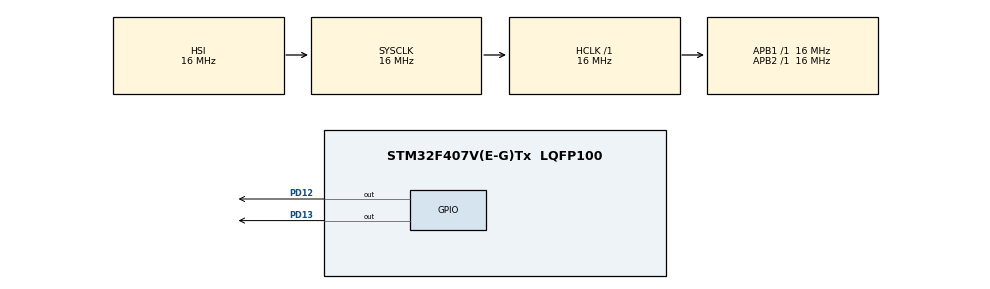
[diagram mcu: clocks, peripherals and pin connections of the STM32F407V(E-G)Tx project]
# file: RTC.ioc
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Mcu.Family=STM32F4
Mcu.Name=STM32F407V(E-G)Tx
Mcu.Package=LQFP100
NVIC.PriorityGroup=NVIC_PRIORITYGROUP_4
NVIC.RTC_Alarm_IRQn=true\:0\:0\:false\:false\:true\:true\:true\:true
PD12.Signal=GPIO_Output
PD13.Signal=GPIO_Output
ProjectManager.HeapSize=0x200
ProjectManager.StackSize=0x400
ProjectManager.TargetToolchain=STM32CubeIDE
RCC.AHBFreq_Value=16000000
RCC.APB1Freq_Value=16000000
RCC.APB2Freq_Value=16000000
RCC.CortexFreq_Value=16000000
RCC.HSE_VALUE=25000000
RCC.HSI_VALUE=16000000
RCC.LSE_VALUE=32768
RCC.SYSCLKFreq_VALUE=16000000
RCC.VCOOutputFreq_Value=192000000
RTC.Alarm=RTC_ALARM_A
RTC.AlarmDateWeekDay=4
RTC.Date=3
RTC.HourFormat=RTC_HOURFORMAT_24
RTC.Hours=23
RTC.Minutes=59
RTC.Month=RTC_MONTH_OCTOBER
RTC.Seconds=59
RTC.Seconds_A=9
RTC.WeekDay=RTC_WEEKDAY_SATURDAY
RTC.Year=0
VP_RTC_VS_RTC_Activate.Mode=RTC_Enabled
VP_RTC_VS_RTC_Alarm_A_Intern.Mode=Alarm A
VP_RTC_VS_RTC_Calendar.Mode=RTC_Calendar
board=custom

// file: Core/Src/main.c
/* USER CODE BEGIN Header */
/**
  ******************************************************************************
  * @file           : main.c
  * @brief          : Main program body
  ******************************************************************************
  * @attention
  *
  * Copyright (c) 2026 STMicroelectronics.
  * All rights reserved.
  *
  * This software is licensed under terms that can be found in the LICENSE file
  * in the root directory of this software component.
  * If no LICENSE file comes with this software, it is provided AS-IS.
  *
  ******************************************************************************
  */
/* USER CODE END Header */
#include "main.h"

RTC_HandleTypeDef hrtc;

void SystemClock_Config(void);
static void MX_GPIO_Init(void);
static void MX_RTC_Init(void);

int main(void)
{

  /* MCU Configuration--------------------------------------------------------*/

  /* Reset of all peripherals, Initializes the Flash interface and the Systick. */
  HAL_Init();

  /* Configure the system clock */
  SystemClock_Config();

  /* Initialize all configured peripherals */
  MX_GPIO_Init();
  MX_RTC_Init();

  /* Infinite loop */
  while (1)
  {

    /* USER CODE BEGIN 3 */
	  HAL_Delay(1000);
	  HAL_GPIO_TogglePin(GPIOD, GPIO_PIN_13);
  }
  /* USER CODE END 3 */
}

void SystemClock_Config(void)
{
  RCC_OscInitTypeDef RCC_OscInitStruct = {0};
  RCC_ClkInitTypeDef RCC_ClkInitStruct = {0};

  /** Configure the main internal regulator output voltage
  */
  __HAL_RCC_PWR_CLK_ENABLE();
  __HAL_PWR_VOLTAGESCALING_CONFIG(PWR_REGULATOR_VOLTAGE_SCALE1);

  /** Initializes the RCC Oscillators according to the specified parameters
  * in the RCC_OscInitTypeDef structure.
  */
  RCC_OscInitStruct.OscillatorType = RCC_OSCILLATORTYPE_HSI|RCC_OSCILLATORTYPE_LSI;
  RCC_OscInitStruct.HSIState = RCC_HSI_ON;
  RCC_OscInitStruct.HSICalibrationValue = RCC_HSICALIBRATION_DEFAULT;
  RCC_OscInitStruct.LSIState = RCC_LSI_ON;
  RCC_OscInitStruct.PLL.PLLState = RCC_PLL_NONE;
  if (HAL_RCC_OscConfig(&RCC_OscInitStruct) != HAL_OK)
  {
    Error_Handler();
  }

  /** Initializes the CPU, AHB and APB buses clocks
  */
  RCC_ClkInitStruct.ClockType = RCC_CLOCKTYPE_HCLK|RCC_CLOCKTYPE_SYSCLK
                              |RCC_CLOCKTYPE_PCLK1|RCC_CLOCKTYPE_PCLK2;
  RCC_ClkInitStruct.SYSCLKSource = RCC_SYSCLKSOURCE_HSI;
  RCC_ClkInitStruct.AHBCLKDivider = RCC_SYSCLK_DIV1;
  RCC_ClkInitStruct.APB1CLKDivider = RCC_HCLK_DIV1;
  RCC_ClkInitStruct.APB2CLKDivider = RCC_HCLK_DIV1;

  if (HAL_RCC_ClockConfig(&RCC_ClkInitStruct, FLASH_LATENCY_0) != HAL_OK)
  {
    Error_Handler();
  }
}

static void MX_RTC_Init(void)
{

  RTC_TimeTypeDef sTime = {0};
  RTC_DateTypeDef sDate = {0};
  RTC_AlarmTypeDef sAlarm = {0};

  /** Initialize RTC Only
  */
  hrtc.Instance = RTC;
  hrtc.Init.HourFormat = RTC_HOURFORMAT_24;
  hrtc.Init.AsynchPrediv = 127;
  hrtc.Init.SynchPrediv = 255;
  hrtc.Init.OutPut = RTC_OUTPUT_DISABLE;
  hrtc.Init.OutPutPolarity = RTC_OUTPUT_POLARITY_HIGH;
  hrtc.Init.OutPutType = RTC_OUTPUT_TYPE_OPENDRAIN;
  if (HAL_RTC_Init(&hrtc) != HAL_OK)
  {
    Error_Handler();
  }

  /** Initialize RTC and set the Time and Date
  */
  sTime.Hours = 0x23;
  sTime.Minutes = 0x59;
  sTime.Seconds = 0x59;
  sTime.DayLightSaving = RTC_DAYLIGHTSAVING_NONE;
  sTime.StoreOperation = RTC_STOREOPERATION_RESET;
  if (HAL_RTC_SetTime(&hrtc, &sTime, RTC_FORMAT_BCD) != HAL_OK)
  {
    Error_Handler();
  }
  sDate.WeekDay = RTC_WEEKDAY_SATURDAY;
  sDate.Month = RTC_MONTH_OCTOBER;
  sDate.Date = 0x3;
  sDate.Year = 0x0;

  if (HAL_RTC_SetDate(&hrtc, &sDate, RTC_FORMAT_BCD) != HAL_OK)
  {
    Error_Handler();
  }

  /** Enable the Alarm A
  */
  sAlarm.AlarmTime.Hours = 0x0;
  sAlarm.AlarmTime.Minutes = 0x0;
  sAlarm.AlarmTime.Seconds = 0x9;
  sAlarm.AlarmTime.SubSeconds = 0x0;
  sAlarm.AlarmTime.DayLightSaving = RTC_DAYLIGHTSAVING_NONE;
  sAlarm.AlarmTime.StoreOperation = RTC_STOREOPERATION_RESET;
  sAlarm.AlarmMask = RTC_ALARMMASK_NONE;
  sAlarm.AlarmSubSecondMask = RTC_ALARMSUBSECONDMASK_ALL;
  sAlarm.AlarmDateWeekDaySel = RTC_ALARMDATEWEEKDAYSEL_DATE;
  sAlarm.AlarmDateWeekDay = 0x4;
  sAlarm.Alarm = RTC_ALARM_A;
  if (HAL_RTC_SetAlarm_IT(&hrtc, &sAlarm, RTC_FORMAT_BCD) != HAL_OK)
  {
    Error_Handler();
  }

}

static void MX_GPIO_Init(void)
{
  GPIO_InitTypeDef GPIO_InitStruct = {0};

  /* GPIO Ports Clock Enable */
  __HAL_RCC_GPIOD_CLK_ENABLE();

  /*Configure GPIO pin Output Level */
  HAL_GPIO_WritePin(GPIOD, GPIO_PIN_12|GPIO_PIN_13, GPIO_PIN_RESET);

  /*Configure GPIO pins : PD12 PD13 */
  GPIO_InitStruct.Pin = GPIO_PIN_12|GPIO_PIN_13;
  GPIO_InitStruct.Mode = GPIO_MODE_OUTPUT_PP;
  GPIO_InitStruct.Pull = GPIO_NOPULL;
  GPIO_InitStruct.Speed = GPIO_SPEED_FREQ_LOW;
  HAL_GPIO_Init(GPIOD, &GPIO_InitStruct);

}

/* USER CODE BEGIN 4 */
void HAL_RTC_AlarmAEventCallback(RTC_HandleTypeDef *hrtc){

	HAL_GPIO_WritePin(GPIOD, GPIO_PIN_12, 1);
}
/* USER CODE END 4 */

void Error_Handler(void)
{
  __disable_irq();
  while (1)
  {
  }
}
